VERSION ""

NS_ :

BS_:

BU_:
	NEO
	MCU
	GTW
	EPAS
	DI
	ESP
	SBW
	STW
	PEDAL

VAL_TABLE_ DI_gear 7 "DI_GEAR_SNA" 4 "DI_GEAR_D" 3 "DI_GEAR_N" 2 "DI_GEAR_R" 1 "DI_GEAR_P" 0 "DI_GEAR_INVALID" ;
VAL_TABLE_ DI_cruiseState 7 "FAULT" 6 "PRE_CANCEL" 5 "PRE_FAULT" 4 "OVERRIDE" 3 "STANDSTILL" 2 "ENABLED" 1 "STANDBY" 0 "OFF" ;
VAL_TABLE_ DI_speedUnits 1 "KPH" 0 "MPH" ;

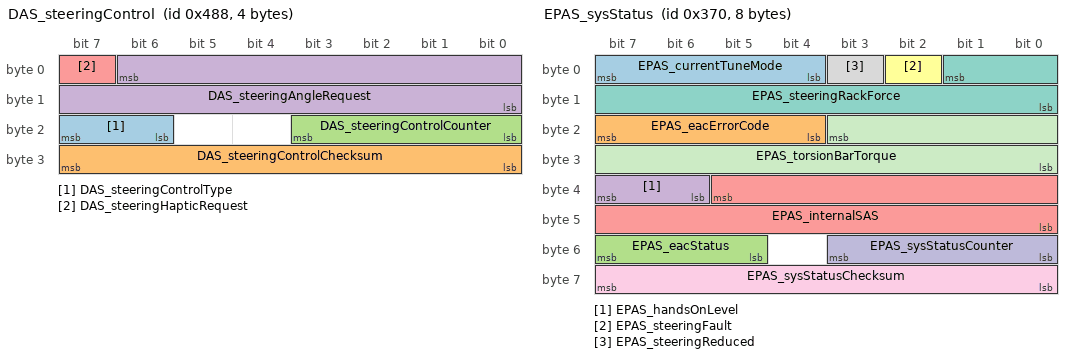
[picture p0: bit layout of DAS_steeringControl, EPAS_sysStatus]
BO_ 1160 DAS_steeringControl: 4 NEO
 SG_ DAS_steeringControlType : 23|2@0+ (1,0) [0|0] "" EPAS
 SG_ DAS_steeringControlChecksum : 31|8@0+ (1,0) [0|0] "" EPAS
 SG_ DAS_steeringControlCounter : 19|4@0+ (1,0) [0|0] "" EPAS
 SG_ DAS_steeringAngleRequest : 6|15@0+ (0.1,-1638.35) [-1638.35|1638.35] "deg" EPAS
 SG_ DAS_steeringHapticRequest : 7|1@0+ (1,0) [0|0] "" EPAS

BO_ 880 EPAS_sysStatus: 8 EPAS
 SG_ EPAS_currentTuneMode : 7|4@0+ (1,0) [8|15] ""  NEO
 SG_ EPAS_eacErrorCode : 23|4@0+ (1,0) [-1|16] ""  NEO
 SG_ EPAS_eacStatus : 55|3@0+ (1,0) [5|7] ""  NEO
 SG_ EPAS_handsOnLevel : 39|2@0+ (1,0) [-1|4] ""  NEO
 SG_ EPAS_internalSAS : 37|14@0+ (0.1,-819.200012) [0|0] "deg"  NEO
 SG_ EPAS_steeringFault : 2|1@0+ (1,0) [-1|2] ""  NEO
 SG_ EPAS_steeringRackForce : 1|10@0+ (50,-25575) [0|0] "N" NEO
 SG_ EPAS_steeringReduced : 3|1@0+ (1,0) [-1|2] ""  NEO
 SG_ EPAS_sysStatusChecksum : 63|8@0+ (1,0) [0|255] ""  NEO
 SG_ EPAS_sysStatusCounter : 51|4@0+ (1,0) [0|15] ""  NEO
 SG_ EPAS_torsionBarTorque : 19|12@0+ (0.01,-20.5) [0|0] "Nm"  NEO

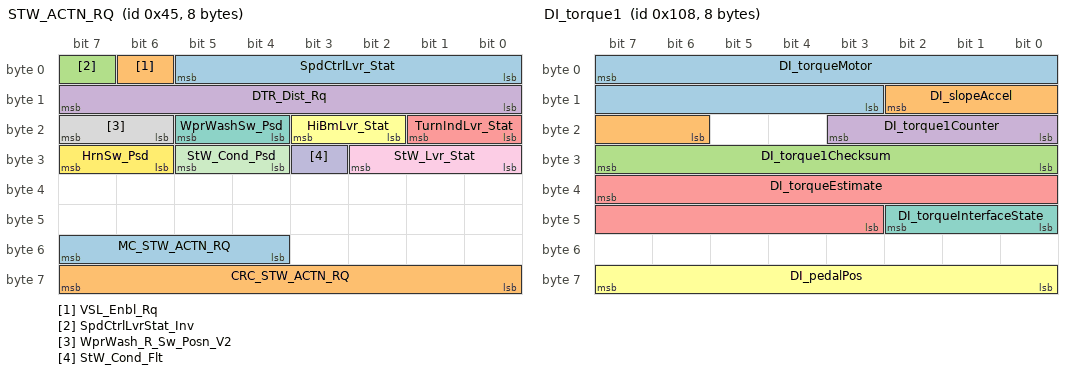
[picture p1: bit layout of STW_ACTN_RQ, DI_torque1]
BO_ 69 STW_ACTN_RQ: 8 STW
 SG_ SpdCtrlLvr_Stat : 0|6@1+ (1,0) [0|0] "" NEO
 SG_ VSL_Enbl_Rq : 6|1@1+ (1,0) [0|0] "" NEO
 SG_ SpdCtrlLvrStat_Inv : 7|1@1+ (1,0) [0|0] "" NEO
 SG_ DTR_Dist_Rq : 8|8@1+ (1,0) [0|200] "" NEO
 SG_ TurnIndLvr_Stat : 16|2@1+ (1,0) [0|0] "" NEO
 SG_ HiBmLvr_Stat : 18|2@1+ (1,0) [0|0] "" NEO
 SG_ WprWashSw_Psd : 20|2@1+ (1,0) [0|0] "" NEO
 SG_ WprWash_R_Sw_Posn_V2 : 22|2@1+ (1,0) [0|0] "" NEO
 SG_ StW_Lvr_Stat : 24|3@1+ (1,0) [0|0] "" NEO
 SG_ StW_Cond_Flt : 27|1@1+ (1,0) [0|0] "" NEO
 SG_ StW_Cond_Psd : 28|2@1+ (1,0) [0|0] "" NEO
 SG_ HrnSw_Psd : 30|2@1+ (1,0) [0|0] "" NEO
 SG_ MC_STW_ACTN_RQ : 52|4@1+ (1,0) [0|15] "" NEO
 SG_ CRC_STW_ACTN_RQ : 56|8@1+ (1,0) [0|0] "" NEO

BO_ 264 DI_torque1: 8 DI
 SG_ DI_torqueMotor : 7|13@0- (0.25,0) [0|0] "Nm" NEO
 SG_ DI_slopeAccel : 10|5@0- (0.2,0) [0|0] "m/s^2" NEO
 SG_ DI_torque1Checksum : 31|8@0+ (1,0) [0|0] "" NEO
 SG_ DI_torque1Counter : 19|4@0+ (1,0) [0|0] "" NEO
 SG_ DI_torqueEstimate : 39|13@0- (2,0) [0|0] "Nm" NEO
 SG_ DI_pedalPos : 63|8@0+ (0.4,0) [0|100] "%" NEO
 SG_ DI_torqueInterfaceState : 42|3@0+ (1,0) [0|0] "" NEO

BO_ 280 DI_torque2: 8 DI
 SG_ DI_gear : 7|3@0+ (1,0) [0|0] "" NEO
 SG_ DI_torqueActual : 4|13@0- (0.25,0) [0|0] "Nm" NEO
 SG_ DI_torque2Checksum : 31|8@0+ (1,0) [0|0] "" NEO
 SG_ DI_torque2Counter : 19|4@0+ (1,0) [0|0] "" NEO
 SG_ DI_brakePedal : 47|8@0+ (1,0) [0|0] "" NEO
 SG_ DI_brakePedalState : 39|2@0+ (1,0) [0|0] "" NEO
 SG_ DI_axleSpeed : 63|16@0+ (0.1,-3200) [0|0] "rad/s" NEO

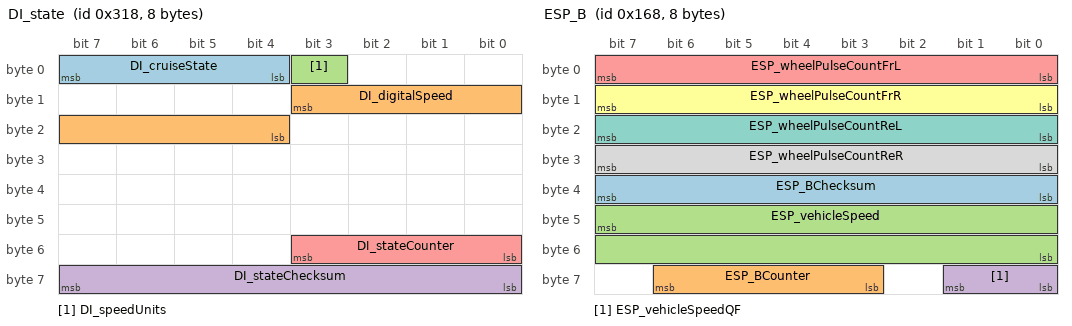
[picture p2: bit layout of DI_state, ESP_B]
BO_ 792 DI_state: 8 DI
 SG_ DI_cruiseState : 7|4@0+ (1,0) [0|0] "" NEO
 SG_ DI_digitalSpeed : 11|8@0+ (1,0) [0|0] "" NEO
 SG_ DI_speedUnits : 3|1@0+ (1,0) [0|0] "" NEO
 SG_ DI_stateChecksum : 63|8@0+ (1,0) [0|0] "" NEO
 SG_ DI_stateCounter : 51|4@0+ (1,0) [0|0] "" NEO

BO_ 360 ESP_B: 8 ESP
 SG_ ESP_BChecksum : 39|8@0+ (1,0) [0|255] ""  NEO,EPAS
 SG_ ESP_BCounter : 62|4@0+ (1,0) [1|15] ""  NEO,EPAS
 SG_ ESP_vehicleSpeed : 47|16@0+ (0.01,0) [0|0] "kph"  NEO,EPAS
 SG_ ESP_vehicleSpeedQF : 57|2@0+ (1,0) [1|2] ""  NEO,EPAS
 SG_ ESP_wheelPulseCountFrL : 7|8@0+ (1,0) [0|254] ""  NEO,EPAS
 SG_ ESP_wheelPulseCountFrR : 15|8@0+ (1,0) [0|254] ""  NEO,EPAS
 SG_ ESP_wheelPulseCountReL : 23|8@0+ (1,0) [0|254] ""  NEO,EPAS
 SG_ ESP_wheelPulseCountReR : 31|8@0+ (1,0) [0|254] ""  NEO,EPAS

BO_ 520 BrakeMessage: 8 ESP
 SG_ driverBrakeStatus : 7|2@0+ (1,0) [0|3] "" NEO
 SG_ brakeForce : 5|14@0+ (1,0) [0|16383] "" NEO

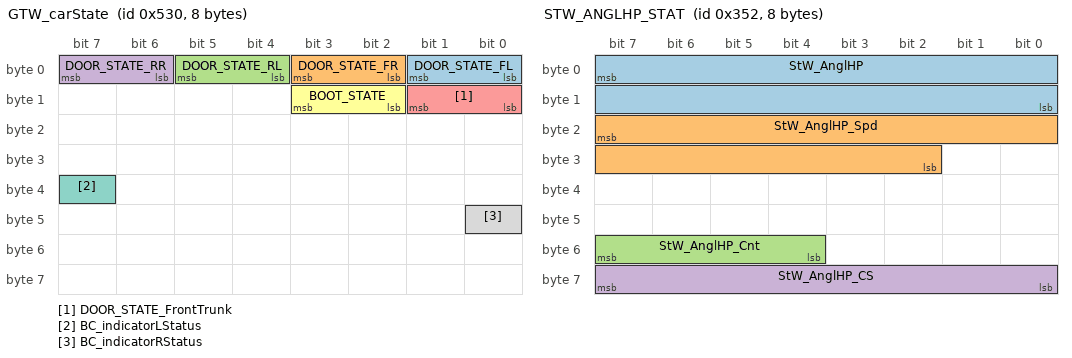
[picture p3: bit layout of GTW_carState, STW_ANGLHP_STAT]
BO_ 1328 GTW_carState: 8 GTW
 SG_ DOOR_STATE_FL : 1|2@0+ (1,0) [0|3] "" NEO
 SG_ DOOR_STATE_FR : 3|2@0+ (1,0) [0|3] "" NEO
 SG_ DOOR_STATE_RL : 5|2@0+ (1,0) [0|3] "" NEO
 SG_ DOOR_STATE_RR : 7|2@0+ (1,0) [0|3] "" NEO
 SG_ DOOR_STATE_FrontTrunk : 9|2@0+ (1,0) [0|3] "" NEO
 SG_ BOOT_STATE : 11|2@0+ (1,0) [0|3] "" NEO
 SG_ BC_indicatorLStatus : 39|1@0+ (1,0) [0|1] "" NEO
 SG_ BC_indicatorRStatus : 40|1@0+ (1,0) [0|1] "" NEO

BO_ 850 STW_ANGLHP_STAT: 8 STW
 SG_ StW_AnglHP : 7|16@0- (0.1,0) [-3276.8|3276.7] "deg" NEO
 SG_ StW_AnglHP_Spd : 23|14@0+ (0.5,0) [0|8191.5] "deg/s" NEO
 SG_ StW_AnglHP_Cnt : 55|4@0+ (1,0) [0|15] "" NEO
 SG_ StW_AnglHP_CS : 63|8@0+ (1,0) [0|255] "" NEO

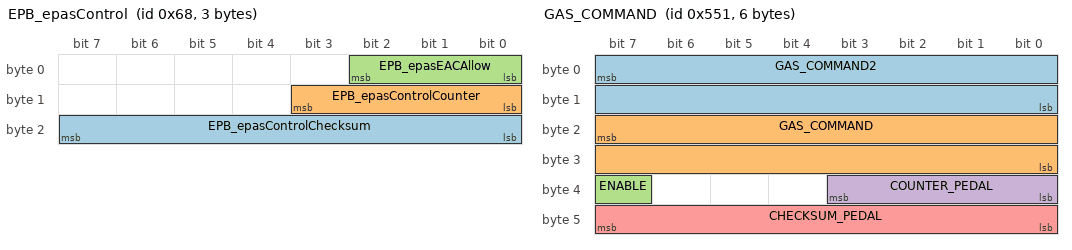
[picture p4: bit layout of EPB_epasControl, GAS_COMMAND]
BO_ 104 EPB_epasControl: 3 EPB
 SG_ EPB_epasControlChecksum : 23|8@0+ (1,0) [0|255] ""  NEO,EPAS
 SG_ EPB_epasControlCounter : 11|4@0+ (1,0) [0|15] ""  NEO,EPAS
 SG_ EPB_epasEACAllow : 2|3@0+ (1,0) [4|7] ""  NEO,EPAS

BO_ 872 SDM1: 8 SDM
 SG_ SDM_bcklDrivStatus : 7|2@0+ (1,0) [0|3] "" NEO

BO_ 1160 RCM_status: 8 RCM
 SG_ RCM_buckleDriverStatus : 7|2@0+ (1,0) [0|3] "" NEO

BO_ 1361 GAS_COMMAND: 6 NEO
 SG_ GAS_COMMAND2 : 7|16@0+ (0.01,0) [0|1] "" PEDAL
 SG_ GAS_COMMAND : 23|16@0+ (0.01,0) [0|1] "" PEDAL
 SG_ ENABLE : 39|1@0+ (1,0) [0|1] "" PEDAL
 SG_ COUNTER_PEDAL : 35|4@0+ (1,0) [0|15] "" PEDAL
 SG_ CHECKSUM_PEDAL : 47|8@0+ (1,0) [0|255] "" PEDAL

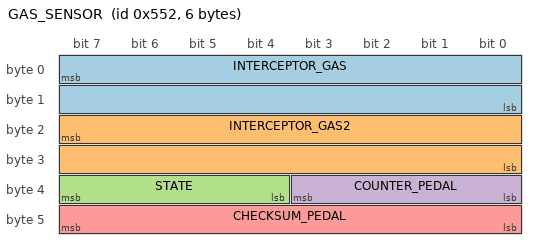
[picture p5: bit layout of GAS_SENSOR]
BO_ 1362 GAS_SENSOR: 6 PEDAL
 SG_ INTERCEPTOR_GAS : 7|16@0+ (0.01,0) [0|1] "" NEO
 SG_ INTERCEPTOR_GAS2 : 23|16@0+ (0.01,0) [0|1] "" NEO
 SG_ STATE : 39|4@0+ (1,0) [0|15] "" NEO
 SG_ COUNTER_PEDAL : 35|4@0+ (1,0) [0|15] "" NEO
 SG_ CHECKSUM_PEDAL : 47|8@0+ (1,0) [0|255] "" NEO

VAL_ 880 EPAS_currentTuneMode 1 "DM_COMFORT" 3 "DM_SPORT" 2 "DM_STANDARD" 0 "FAIL_SAFE_DEFAULT" 4 "RWD_COMFORT" 6 "RWD_SPORT" 5 "RWD_STANDARD" 7 "UNAVAILABLE" ;
VAL_ 880 EPAS_eacErrorCode 14 "EAC_ERROR_EPB_INHIBIT" 3 "EAC_ERROR_HANDS_ON" 7 "EAC_ERROR_HIGH_ANGLE_RATE_REQ" 9 "EAC_ERROR_HIGH_ANGLE_RATE_SAFETY" 6 "EAC_ERROR_HIGH_ANGLE_REQ" 8 "EAC_ERROR_HIGH_ANGLE_SAFETY" 10 "EAC_ERROR_HIGH_MMOT_SAFETY" 11 "EAC_ERROR_HIGH_TORSION_SAFETY" 0 "EAC_ERROR_IDLE" 12 "EAC_ERROR_LOW_ASSIST" 2 "EAC_ERROR_MAX_SPEED" 1 "EAC_ERROR_MIN_SPEED" 13 "EAC_ERROR_PINION_VEL_DIFF" 4 "EAC_ERROR_TMP_FAULT" 5 "EAR_ERROR_MAX_STEER_DELTA" 15 "SNA" ;
VAL_ 880 EPAS_eacStatus 2 "EAC_ACTIVE" 1 "EAC_AVAILABLE" 3 "EAC_FAULT" 0 "EAC_INHIBITED" 4 "SNA" ;
VAL_ 880 EPAS_handsOnLevel 0 "0" 1 "1" 2 "2" 3 "3" ;
VAL_ 880 EPAS_steeringFault 1 "FAULT" 0 "NO_FAULT" ;
VAL_ 880 EPAS_steeringReduced 0 "NORMAL_ASSIST" 1 "REDUCED_ASSIST" ;
VAL_ 792 DI_cruiseState 7 "FAULT" 6 "PRE_CANCEL" 5 "PRE_FAULT" 4 "OVERRIDE" 3 "STANDSTILL" 2 "ENABLED" 1 "STANDBY" 0 "OFF" ;
VAL_ 792 DI_speedUnits 1 "KPH" 0 "MPH" ;
VAL_ 280 DI_gear 7 "DI_GEAR_SNA" 4 "DI_GEAR_D" 3 "DI_GEAR_N" 2 "DI_GEAR_R" 1 "DI_GEAR_P" 0 "DI_GEAR_INVALID" ;
VAL_ 1328 DOOR_STATE_FL 2 "AJAR" 1 "CLOSED" 0 "OPEN" 3 "SNA" ;
VAL_ 1328 DOOR_STATE_FR 2 "AJAR" 1 "CLOSED" 0 "OPEN" 3 "SNA" ;
VAL_ 1328 DOOR_STATE_RL 2 "AJAR" 1 "CLOSED" 0 "OPEN" 3 "SNA" ;
VAL_ 1328 DOOR_STATE_RR 2 "AJAR" 1 "CLOSED" 0 "OPEN" 3 "SNA" ;
VAL_ 1328 DOOR_STATE_FrontTrunk 2 "AJAR" 1 "CLOSED" 0 "OPEN" 3 "SNA" ;
VAL_ 1328 BOOT_STATE 2 "AJAR" 1 "CLOSED" 0 "OPEN" 3 "SNA" ;
VAL_ 1160 DAS_steeringControlType 2 "LANE_KEEP_ASSIST" 0 "NONE" 1 "ANGLE_CONTROL" 3 "EMERGENCY_LANE_KEEP" ;
VAL_ 1362 STATE 5 "TIMEOUT" 4 "RESERVED" 3 "RESERVED2" 2 "RESERVED3" 1 "BAD_CHECKSUM" 0 "OK" ;
